# G32R502 register map
Vendor: Geehy Semiconductor Co., Ltd.; Series: G32R5; File version: 1.0
CPU: CM52 r0p1, little endian, MPU, FPU, DSP, VTOR, 4 interrupt priority bits
Registers are 32-bit, read-write, reset 0x0 unless marked. A register's access mark holds for its fields unless they carry their own. Offsets are from the block's base; [hi:lo] are bit positions; {n}, {i} and the like mark numbered series.

## GPIOCTRL — GPIO CTRL Registers
Base 0x40030000
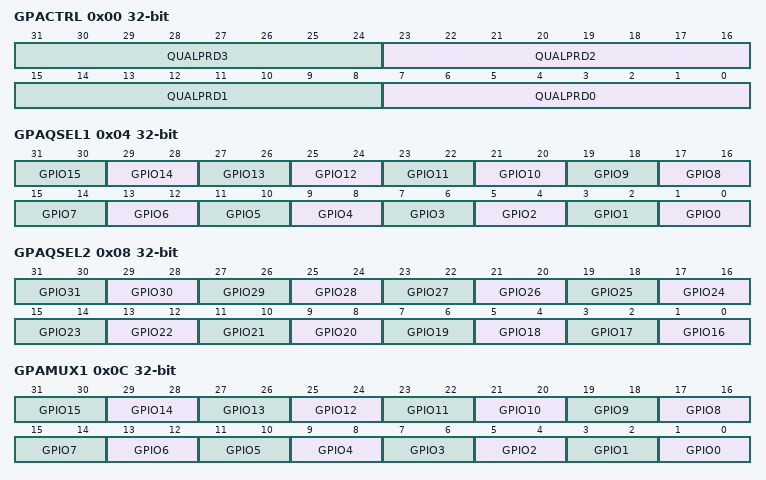
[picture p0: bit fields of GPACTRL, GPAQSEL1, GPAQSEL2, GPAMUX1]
0x00 GPACTRL — GPIO A Qualification Sampling Period (GPIO0 to GPIO31)
  [8n+7:8n] QUALPRD{n} (n=0..3) — GPIO{8n} to GPIO{8n+7} sampling cycle
0x04 GPAQSEL1 — GPIO A Qualification Type (GPIO0 to GPIO15)
  [2n+1:2n] GPIO{n} (n=0..15) — GPIO{n} Input type
0x08 GPAQSEL2 — GPIO A Qualification Type (GPIO16 to GPIO31)
  [2n-31:2n-32] GPIO{n} (n=16..31) — GPIO{n} Input type
0x0C GPAMUX1 — GPIO A Peripheral Mux (GPIO0 to GPIO15)
  [2n+1:2n] GPIO{n} (n=0..15) — GPIO{n} peripheral mux configuration in the low 2 bits
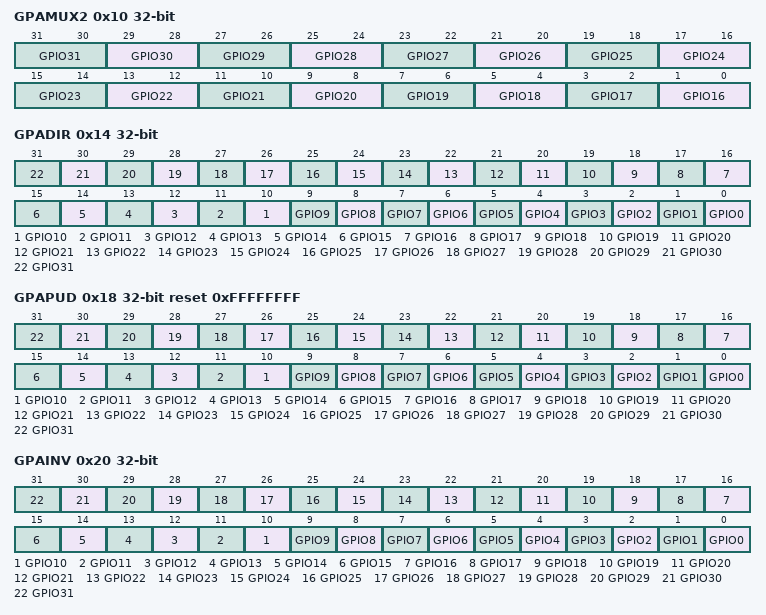
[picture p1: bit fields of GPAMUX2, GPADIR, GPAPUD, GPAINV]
0x10 GPAMUX2 — GPIO A Peripheral Mux (GPIO16 to GPIO31)
  [2n-31:2n-32] GPIO{n} (n=16..31) — GPIO{n} peripheral mux configuration in the low 2 bits
0x14 GPADIR — GPIO A Direction (GPIO0 to GPIO31)
  [n] GPIO{n} (n=0..31) — GPIO{n} Data direction
0x18 GPAPUD reset 0xFFFFFFFF — GPIO A Pull-Up Disable (GPIO0 to GPIO31)
  [n] GPIO{n} (n=0..31) — GPIO{n} Pull-up disable
0x20 GPAINV — GPIO A Input Inversion (GPIO0 to GPIO31)
  [n] GPIO{n} (n=0..31) — GPIO{n} Input inversion
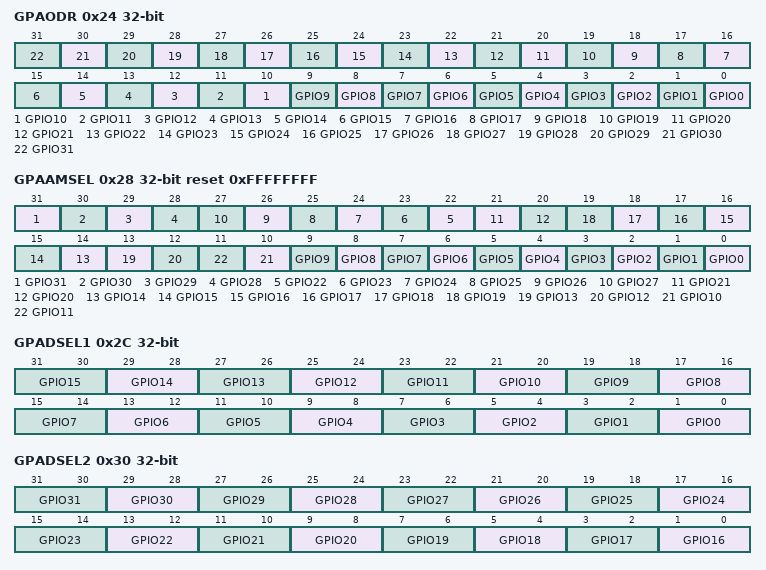
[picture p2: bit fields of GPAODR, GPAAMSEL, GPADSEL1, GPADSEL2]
0x24 GPAODR — GPIO A Open Drain Output Mode (GPIO0 to GPIO31)
  [n] GPIO{n} (n=0..31) — GPIO{n} Open-drain output mode
0x28 GPAAMSEL reset 0xFFFFFFFF — GPIO A Analog Mode Select (GPIO0 to GPIO31)
  [31] GPIO31
  [30] GPIO30
  [29] GPIO29
  [28] GPIO28 — Analog mode select for GPIO28
  [n] GPIO{n} (n=22..27)
  [21] GPIO21 — Analog mode select for GPIO21
  [20] GPIO20 — Analog mode select for GPIO20
  [n] GPIO{n} (n=14..19)
  [13] GPIO13 — Analog mode select for GPIO13
  [12] GPIO12 — Analog mode select for GPIO12
  [n] GPIO{n} (n=0..11)
0x2C GPADSEL1
  [2n+1:2n] GPIO{n} (n=0..15) — Driver capability select for GPIO{n}
0x30 GPADSEL2
  [2n-31:2n-32] GPIO{n} (n=16..31) — Driver capability select for GPIO{n}
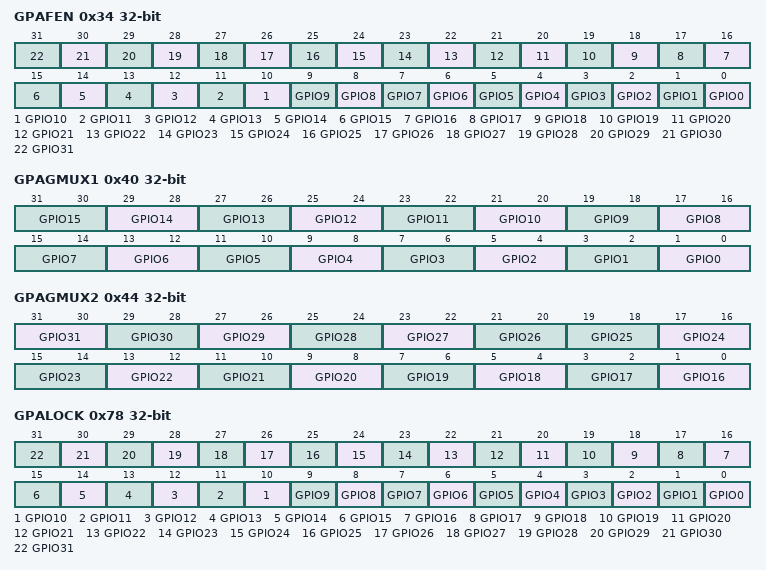
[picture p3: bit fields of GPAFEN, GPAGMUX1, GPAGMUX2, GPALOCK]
0x34 GPAFEN
  [n] GPIO{n} (n=0..31) — GPIO{n} Maximum Output Frequency Enable
0x40 GPAGMUX1 — GPIO A Peripheral Group Mux (GPIO0 to GPIO15)
  [2n+1:2n] GPIO{n} (n=0..15) — GPIO{n} peripheral mux configuration in the High 2 bits
0x44 GPAGMUX2 — GPIO A Peripheral Group Mux (GPIO16 to GPIO31)
  [2n-31:2n-32] GPIO{n} (n=27..31) — GPIO{n} peripheral mux configuration in the High 2 bits
  [21:20] GPIO26 — GPIO126 peripheral mux configuration in the High 2 bits
  [2n-31:2n-32] GPIO{n} (n=16..25) — GPIO{n} peripheral mux configuration in the High 2 bits
0x78 GPALOCK — GPIO A Lock Register (GPIO0 to GPIO31)
  [n] GPIO{n} (n=0..31) — GPIO{n} Configuration lock
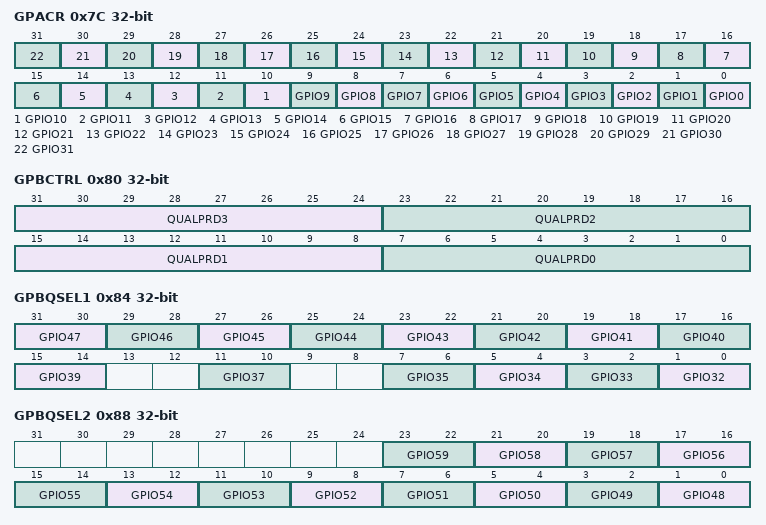
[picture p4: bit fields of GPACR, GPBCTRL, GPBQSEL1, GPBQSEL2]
0x7C GPACR — GPIO A Lock Commit Register (GPIO0 to GPIO31)
  [n] GPIO{n} (n=0..31) — GPIO{n} lock is locked
0x80 GPBCTRL — GPIO B Qualification Sampling Period (GPIO32 to GPIO49)
  [31:24] QUALPRD3 — GPIO56 to GPIO59 sampling cycle
  [23:16] QUALPRD2 — GPIO48 to GPIO55 sampling cycle
  [15:8] QUALPRD1 — GPIO40 to GPIO47 sampling cycle
  [7:0] QUALPRD0 — GPIO32 to GPIO39 sampling cycle
0x84 GPBQSEL1 — GPIO B Qualification Type (GPIO32 to GPIO47)
  [2n-63:2n-64] GPIO{n} (n=39..47) — GPIO{n} Input type
  [11:10] GPIO37 — GPIO37 Input type
  [2n-63:2n-64] GPIO{n} (n=32..35) — GPIO{n} Input type
0x88 GPBQSEL2 — GPIO B Qualification Type (GPIO48 to GPIO49)
  [2n-95:2n-96] GPIO{n} (n=48..59) — GPIO{n} Input type
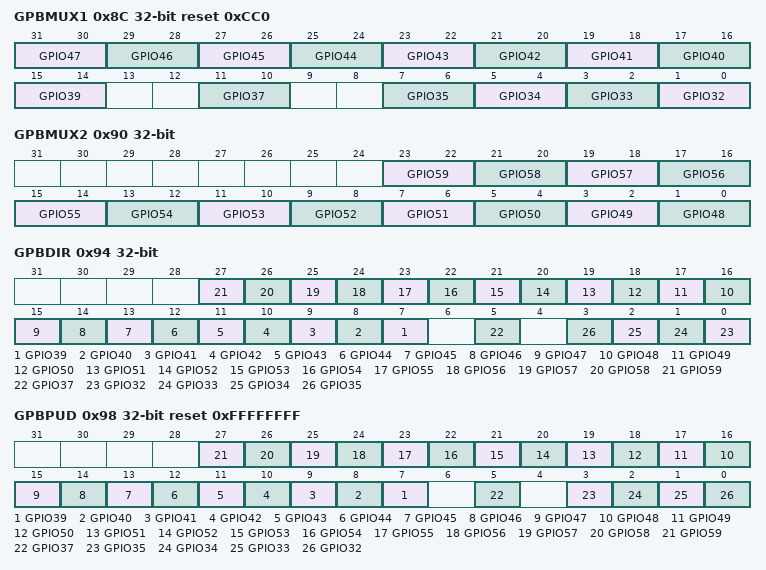
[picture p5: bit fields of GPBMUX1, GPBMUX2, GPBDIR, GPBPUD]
0x8C GPBMUX1 reset 0xCC0 — GPIO B Peripheral Mux (GPIO32 to GPIO47)
  [2n-63:2n-64] GPIO{n} (n=39..47) — GPIO{n} peripheral mux configuration in the low 2 bits
  [11:10] GPIO37 — GPIO37 peripheral mux configuration in the low 2 bits
  [2n-63:2n-64] GPIO{n} (n=32..35) — GPIO{n} peripheral mux configuration in the low 2 bits
0x90 GPBMUX2 — GPIO B Peripheral Mux (GPIO48 to GPIO49)
  [23:22] GPIO59 — GPIO4859 peripheral mux configuration in the low 2 bits
  [2n-95:2n-96] GPIO{n} (n=48..58) — GPIO{n} peripheral mux configuration in the low 2 bits
0x94 GPBDIR — GPIO B Direction (GPIO32 to GPIO49)
  [n-32] GPIO{n} (n=39..59) — GPIO{n} Data direction
  [5] GPIO37 — GPIO37 Data direction
  [n-32] GPIO{n} (n=32..35) — GPIO{n} Data direction
0x98 GPBPUD reset 0xFFFFFFFF — GPIO B Pull-Up Disable (GPIO32 to GPIO49)
  [n-32] GPIO{n} (n=39..59) — GPIO{n} Pull-up disable
  [5] GPIO37 — GPIO37 Pull-up disable
  [3] GPIO35 — GPIO35 Pull-up disable
  [2] GPIO34 — GPIO34 Pull-up disable
  [1] GPIO33 — GPIO32 Pull-up disable
  [0] GPIO32 — GPIO32 Pull-up disable
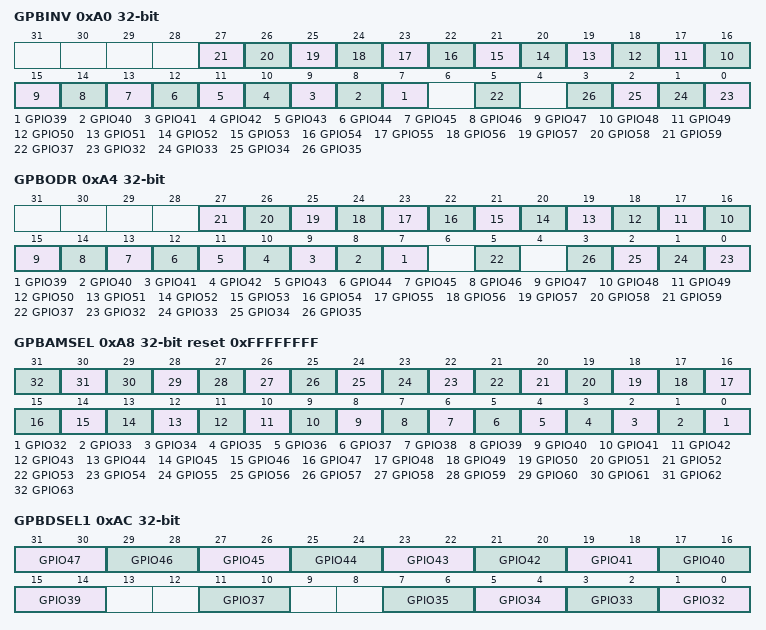
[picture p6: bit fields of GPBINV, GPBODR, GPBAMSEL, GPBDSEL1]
0xA0 GPBINV — GPIO B Input Inversion (GPIO32 to GPIO49)
  [n-32] GPIO{n} (n=39..59) — GPIO{n} Input inversion
  [5] GPIO37 — GPIO37 Input inversion
  [n-32] GPIO{n} (n=32..35) — GPIO{n} Input inversion
0xA4 GPBODR — GPIO B Open Drain Output Mode (GPIO32 to GPIO49)
  [n-32] GPIO{n} (n=39..59) — GPIO{n} Open-drain output mode
  [5] GPIO37 — GPIO37 Open-drain output mode
  [n-32] GPIO{n} (n=32..35) — GPIO{n} Open-drain output mode
0xA8 GPBAMSEL reset 0xFFFFFFFF — GPIO B Analog Mode Select (GPIO32 to GPIO63)
  [n-32] GPIO{n} (n=32..63)
0xAC GPBDSEL1
  [2n-63:2n-64] GPIO{n} (n=39..47) — Driver capability select for GPIO{n}
  [11:10] GPIO37 — Driver capability select for GPIO37
  [2n-63:2n-64] GPIO{n} (n=32..35) — Driver capability select for GPIO{n}
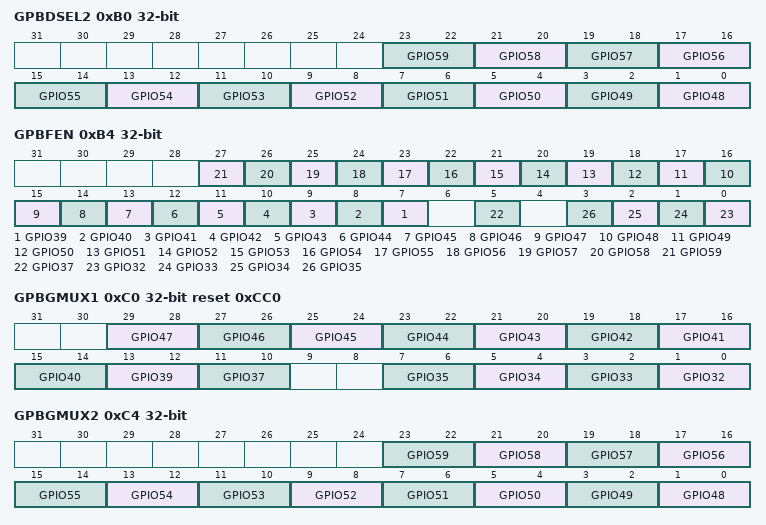
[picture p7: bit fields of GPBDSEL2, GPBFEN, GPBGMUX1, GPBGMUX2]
0xB0 GPBDSEL2
  [2n-95:2n-96] GPIO{n} (n=48..59) — Driver capability select for GPIO{n}
0xB4 GPBFEN
  [n-32] GPIO{n} (n=39..59) — GPIO{n} Maximum Output Frequency Enable
  [5] GPIO37 — GPIO37 Maximum Output Frequency Enable
  [n-32] GPIO{n} (n=32..35) — GPIO{n} Maximum Output Frequency Enable
0xC0 GPBGMUX1 reset 0xCC0 — GPIO B Peripheral Group Mux (GPIO32 to GPIO47)
  [2n-65:2n-66] GPIO{n} (n=39..47) — GPIO{n} peripheral mux configuration in the High 2 bits
  [11:10] GPIO37 — GPIO37 peripheral mux configuration in the High 2 bits
  [2n-63:2n-64] GPIO{n} (n=32..35) — GPIO{n} peripheral mux configuration in the High 2 bits
0xC4 GPBGMUX2 — GPIO B Peripheral Group Mux (GPIO48 to GPIO49)
  [2n-95:2n-96] GPIO{n} (n=48..59) — GPIO{n} peripheral mux configuration in the High 2 bits
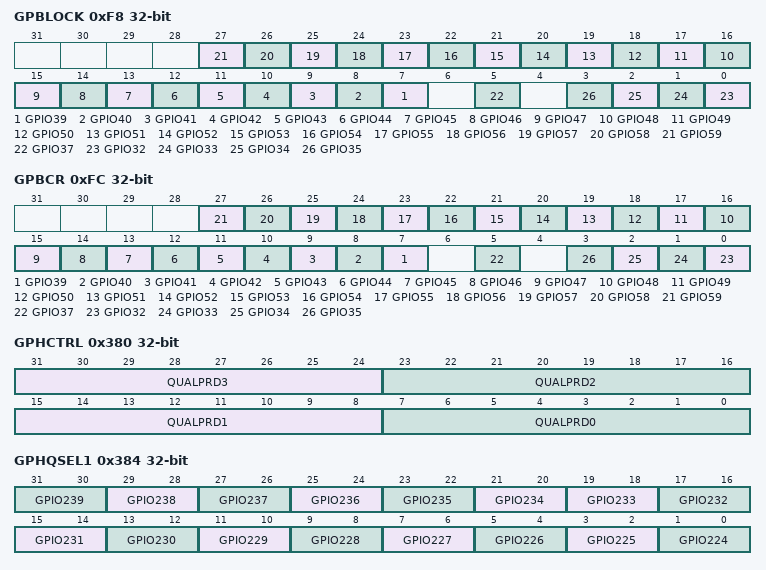
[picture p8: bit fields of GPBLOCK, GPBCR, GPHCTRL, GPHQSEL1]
0xF8 GPBLOCK — GPIO B Lock Register (GPIO32 to GPIO49)
  [n-32] GPIO{n} (n=39..59) — GPIO{n} Configuration lock
  [5] GPIO37 — GPIO37 Configuration lock
  [n-32] GPIO{n} (n=32..35) — GPIO{n} Configuration lock
0xFC GPBCR — GPIO B Lock Commit Register (GPIO32 to GPIO49)
  [n-32] GPIO{n} (n=39..59) — GPIO{n} lock is locked
  [5] GPIO37 — GPIO37 lock is locked
  [n-32] GPIO{n} (n=32..35) — GPIO{n} lock is locked
0x380 GPHCTRL — GPIO H Qualification Sampling Period (GPIO224 to GPIO245)
  [31:24] QUALPRD3 — GPIO248 to GPIO254 sampling cycle
  [23:16] QUALPRD2 — GPIO240 to GPIO247 sampling cycle
  [15:8] QUALPRD1 — GPIO232 to GPIO239 sampling cycle
  [7:0] QUALPRD0 — GPIO224 to GPIO231 sampling cycle
0x384 GPHQSEL1 — GPIO H Qualification Type (GPIO224 to GPIO239)
  [2n-447:2n-448] GPIO{n} (n=234..239) — GPIO{n} Input type
  [19:18] GPIO233 — GPIO2333 Input type
  [2n-447:2n-448] GPIO{n} (n=224..232) — GPIO{n} Input type
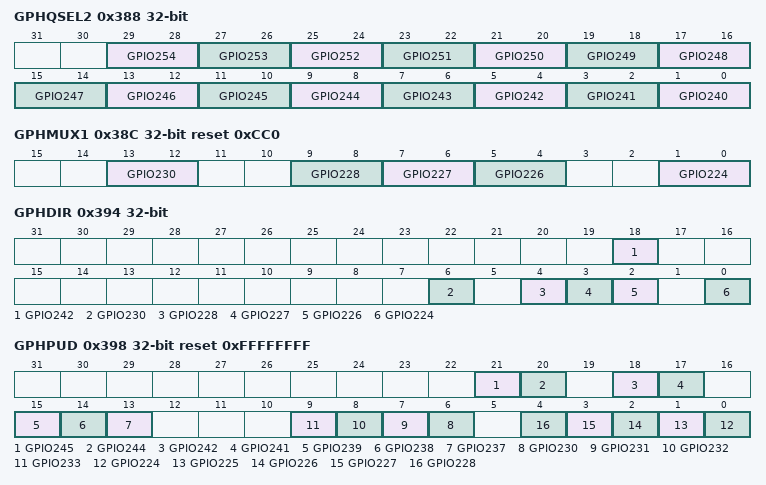
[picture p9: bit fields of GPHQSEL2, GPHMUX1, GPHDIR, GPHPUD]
0x388 GPHQSEL2 — GPIO H Qualification Type (GPIO240 to GPIO245)
  [2n-479:2n-480] GPIO{n} (n=240..254) — GPIO{n} Input type
0x38C GPHMUX1 reset 0xCC0 — GPIO H Peripheral Mux (GPIO240 to GPIO245)
  [13:12] GPIO230 — GPIO230 peripheral mux configuration in the low 2 bits
  [9:8] GPIO228 — GPIO228 peripheral mux configuration in the low 2 bits
  [7:6] GPIO227 — GPIO227 peripheral mux configuration in the low 2 bits
  [5:4] GPIO226 — GPIO226 peripheral mux configuration in the low 2 bits
  [1:0] GPIO224 — GPIO224 peripheral mux configuration in the low 2 bits
0x390 GPHMUX2 — GPIO H Peripheral Mux (GPIO240 to GPIO245)
  [5:4] GPIO242 — GPIO242 peripheral mux configuration in the low 2 bits
0x394 GPHDIR — GPIO H Direction (GPIO240 to GPIO245)
  [18] GPIO242 — GPIO242 Data direction
  [6] GPIO230 — GPIO230 Data direction
  [4] GPIO228 — GPIO228 Data direction
  [3] GPIO227 — GPIO227 Data direction
  [2] GPIO226 — GPIO226 Data direction
  [0] GPIO224 — GPIO224 Data direction
0x398 GPHPUD reset 0xFFFFFFFF — GPIO H Pull-Up Disable (GPIO224 to GPIO245)
  [21] GPIO245 — GPIO245 Pull-up disable
  [20] GPIO244 — GPIO244 Pull-up disable
  [18] GPIO242 — GPIO242 Pull-up disable
  [17] GPIO241 — GPIO241 Pull-up disable
  [15] GPIO239 — GPIO239 Pull-up disable
  [14] GPIO238 — GPIO238 Pull-up disable
  [13] GPIO237 — GPIO237 Pull-up disable
  [n-224] GPIO{n} (n=230..233) — GPIO{n} Pull-up disable
  [n-224] GPIO{n} (n=224..228) — GPIO{n} Pull-up disable
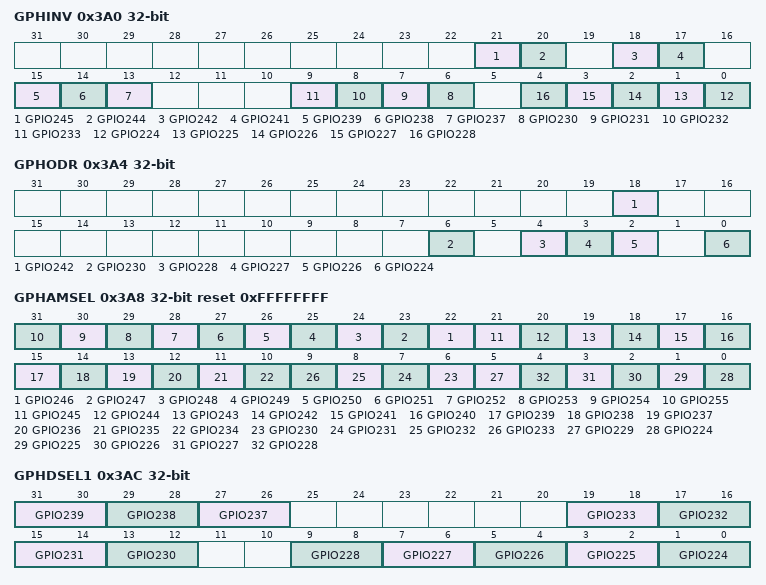
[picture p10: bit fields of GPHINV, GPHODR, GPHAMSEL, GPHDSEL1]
0x3A0 GPHINV — GPIO H Input Inversion (GPIO224 to GPIO245)
  [21] GPIO245 — GPIO245 Input inversion
  [20] GPIO244 — GPIO244 Input inversion
  [18] GPIO242 — GPIO242 Input inversion
  [17] GPIO241 — GPIO241 Input inversion
  [15] GPIO239 — GPIO239 Input inversion
  [14] GPIO238 — GPIO238 Input inversion
  [13] GPIO237 — GPIO237 Input inversion
  [n-224] GPIO{n} (n=230..233) — GPIO{n} Input inversion
  [n-224] GPIO{n} (n=224..228) — GPIO{n} Input inversion
0x3A4 GPHODR — GPIO H Open Drain Output Mode (GPIO224 to GPIO245)
  [18] GPIO242 — GPIO242 Open-drain output mode
  [6] GPIO230 — GPIO230 Open-drain output mode
  [4] GPIO228 — GPIO228 Open-drain output mode
  [3] GPIO227 — GPIO227 Open-drain output mode
  [2] GPIO226 — GPIO226 Open-drain output mode
  [0] GPIO224 — GPIO224 Open-drain output mode
0x3A8 GPHAMSEL reset 0xFFFFFFFF — GPIO H Analog Mode Select (GPIO224 to GPIO245)
  [n-224] GPIO{n} (n=246..255)
  [21] GPIO245 — Analog mode select for GPIO245
  [20] GPIO244 — Analog mode select for GPIO244
  [19] GPIO243
  [18] GPIO242 — Analog mode select for GPIO242
  [17] GPIO241 — Analog mode select for GPIO241
  [16] GPIO240
  [15] GPIO239 — Analog mode select for GPIO239
  [14] GPIO238 — Analog mode select for GPIO238
  [13] GPIO237 — Analog mode select for GPIO237
  [12] GPIO236
  [11] GPIO235
  [10] GPIO234
  [n-224] GPIO{n} (n=230..233) — Analog mode select for GPIO{n}
  [5] GPIO229
  [n-224] GPIO{n} (n=224..228) — Analog mode select for GPIO{n}
0x3AC GPHDSEL1
  [31:30] GPIO239 — Driver capability select for GPIO239
  [29:28] GPIO238 — Driver capability select for GPIO238
  [27:26] GPIO237 — Driver capability select for GPIO237
  [2n-447:2n-448] GPIO{n} (n=230..233) — Driver capability select for GPIO{n}
  [2n-447:2n-448] GPIO{n} (n=224..228) — Driver capability select for GPIO{n}
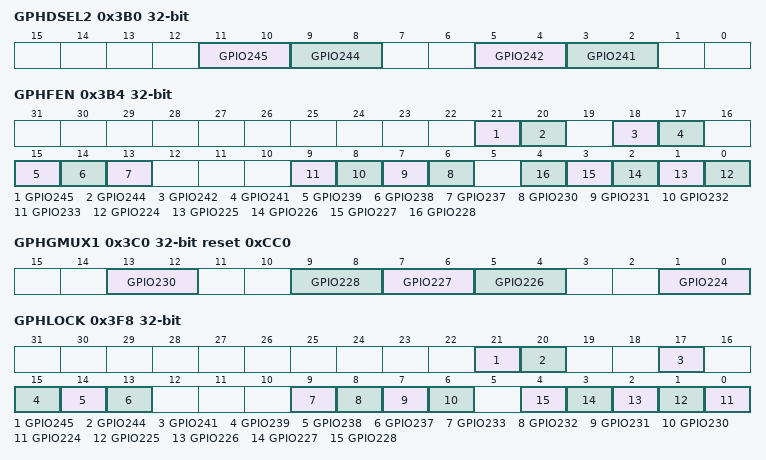
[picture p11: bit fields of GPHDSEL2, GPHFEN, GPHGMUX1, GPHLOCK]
0x3B0 GPHDSEL2
  [11:10] GPIO245 — Driver capability select for GPIO245
  [9:8] GPIO244 — Driver capability select for GPIO244
  [5:4] GPIO242 — Driver capability select for GPIO242
  [3:2] GPIO241 — Driver capability select for GPIO241
0x3B4 GPHFEN
  [21] GPIO245 — GPIO245 Maximum Output Frequency Enable
  [20] GPIO244 — GPIO244 Maximum Output Frequency Enable
  [18] GPIO242 — GPIO242 Maximum Output Frequency Enable
  [17] GPIO241 — GPIO241 Maximum Output Frequency Enable
  [15] GPIO239 — GPIO239 Maximum Output Frequency Enable
  [14] GPIO238 — GPIO238 Maximum Output Frequency Enable
  [13] GPIO237 — GPIO237 Maximum Output Frequency Enable
  [n-224] GPIO{n} (n=230..233) — GPIO{n} Maximum Output Frequency Enable
  [n-224] GPIO{n} (n=224..228) — GPIO{n} Maximum Output Frequency Enable
0x3C0 GPHGMUX1 reset 0xCC0 — GPIO H Peripheral Group Mux (GPIO224 to GPIO239)
  [13:12] GPIO230 — GPIO230 peripheral mux configuration in the High 2 bits
  [9:8] GPIO228 — GPIO228 peripheral mux configuration in the High 2 bits
  [7:6] GPIO227 — GPIO227 peripheral mux configuration in the High 2 bits
  [5:4] GPIO226 — GPIO226 peripheral mux configuration in the High 2 bits
  [1:0] GPIO224 — GPIO224 peripheral mux configuration in the High 2 bits
0x3C4 GPHGMUX2 — GPIO H Peripheral Group Mux (GPIO241 to GPIO245)
  [5:4] GPIO242 — GPIO242 peripheral mux configuration in the High 2 bits
0x3F8 GPHLOCK — GPIO H Lock Register (GPIO224 to GPIO245)
  [21] GPIO245 — GPIO245 Configuration lock
  [20] GPIO244 — GPIO244 Configuration lock
  [17] GPIO241 — GPIO241 Configuration lock
  [15] GPIO239 — GPIO239 Configuration lock
  [14] GPIO238 — GPIO238 Configuration lock
  [13] GPIO237 — GPIO237 Configuration lock
  [9] GPIO233 — GPIO233 Configuration lock
  [8] GPIO232 — GPIO233 Configuration lock
  [7] GPIO231 — GPIO231 Configuration lock
  [6] GPIO230 — GPIO230 Configuration lock
  [n-224] GPIO{n} (n=224..228) — GPIO{n} Configuration lock
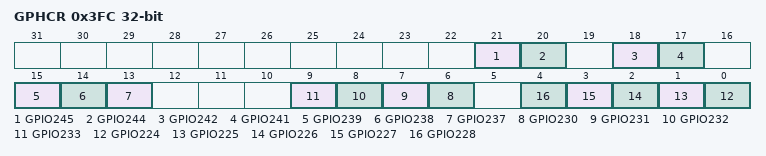
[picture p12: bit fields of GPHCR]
0x3FC GPHCR — GPIO H Lock Commit Register (GPIO224 to GPIO245)
  [21] GPIO245 — GPIO242 lock is locked
  [20] GPIO244 — GPIO244 lock is locked
  [18] GPIO242 — GPIO242 lock is locked
  [17] GPIO241 — GPIO241 lock is locked
  [15] GPIO239 — GPIO239 lock is locked
  [14] GPIO238 — GPIO238 lock is locked
  [13] GPIO237 — GPIO237 lock is locked
  [n-224] GPIO{n} (n=230..233) — GPIO{n} lock is locked
  [n-224] GPIO{n} (n=224..228) — GPIO{n} lock is locked
